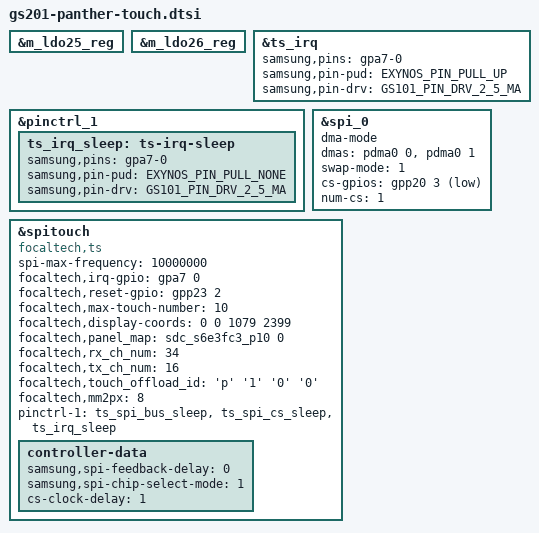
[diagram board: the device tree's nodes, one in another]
// SPDX-License-Identifier: GPL-2.0-only
/*
 * Google P10 touch device tree source
 *
 * Copyright 2021 Google Inc.
 *
 */

#include <arm64/exynos/exynos-pinctrl.h>
#include "gs201/gs101-pinctrl.h"

&m_ldo25_reg {
	/delete-property/ regulator-always-on;
};

&m_ldo26_reg {
	/delete-property/ regulator-always-on;
};

/*
 * Touch is connected to spi_0, pins:
 *   CLK=GPP20[0], MOSI=GPP20[1], MISO=GPP20[2], CS=GPP20[3]
 * TS_RESET_L = C26 = XAPC_USI11_RTSN_DI = GPP23[2] = <&gpp23 2 0>
 * TS_INT_L = AT22 = XEINT_8 = GPA7[0] = <&gpa7 0 0>
 *
 * DVDD = PP1800_L25M_TSP_DVDD = ??? = VLDO25M = "PP1800_L25M_TSP"?
 * AVDD = PP3300_L26M_TS_AVDD  = ??? = VLDO26M = "PP3300_L26M_TSP"?
 *
 * AP2AOC: XHSI1_GPIO2 - GPH1[0] -> XAOC_GPIO13 - gpio_in[87]
 * AOC2AP: XAOC_GPIO8 - gpio_in[74] -> XEINT_19 - GPA8[7]
 */

&ts_irq {
	samsung,pins = "gpa7-0";
	samsung,pin-pud = <EXYNOS_PIN_PULL_UP>;
	samsung,pin-drv = <GS101_PIN_DRV_2_5_MA>;
};


&pinctrl_1 {
	ts_irq_sleep: ts-irq-sleep {
		samsung,pins = "gpa7-0";
		samsung,pin-pud = <EXYNOS_PIN_PULL_NONE>;
		samsung,pin-drv = <GS101_PIN_DRV_2_5_MA>;
	};
};

&spi_0 {
	dma-mode;
	dmas = <&pdma0 0 &pdma0 1>;
	swap-mode = <1> ;

	cs-gpios = <&gpp20 3 GPIO_ACTIVE_LOW>;
	num-cs = <1>;
};

&spitouch {
	status = "ok";
	compatible = "focaltech,ts";

	spi-max-frequency = <10000000>;

	focaltech,irq-gpio = <&gpa7 0 0>;
	focaltech,reset-gpio = <&gpp23 2 0>;
	focaltech,max-touch-number = <10>;
	focaltech,display-coords = <0 0 1079 2399>;
	focaltech,panel_map = <&sdc_s6e3fc3_p10 0>;
	focaltech,rx_ch_num = <34>;
	focaltech,tx_ch_num = <16>;
	focaltech,touch_offload_id = /bits/ 8 <'p' '1' '0' '0'>;
	focaltech,mm2px= /bits/ 8 <8>;

	pinctrl-1 = <&ts_spi_bus_sleep &ts_spi_cs_sleep &ts_irq_sleep>;

	controller-data {
		samsung,spi-feedback-delay = <0>;
		samsung,spi-chip-select-mode = <1>;
		cs-clock-delay = <1>;
	};
};
